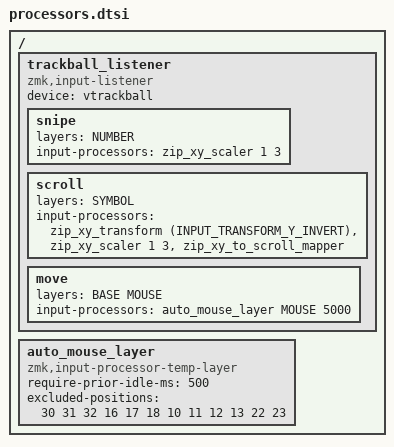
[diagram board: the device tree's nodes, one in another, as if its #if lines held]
/ {
  // Charybdis-specific processors
  #ifdef CHARYBDIS
  trackball_listener {
    compatible = "zmk,input-listener";
    device = <&vtrackball>;

    snipe {
      layers = <NUMBER>;
      input-processors = <&zip_xy_scaler 1 3>;
    };

    scroll {
      layers = <SYMBOL>;
      input-processors = <&zip_xy_transform (INPUT_TRANSFORM_Y_INVERT)>, 
        <&zip_xy_scaler 1 3>, 
        <&zip_xy_to_scroll_mapper>;
    };

    move {
      layers = <BASE MOUSE>;
      input-processors = <&auto_mouse_layer MOUSE 5000>;
    };
  };

  auto_mouse_layer: auto_mouse_layer {
    compatible = "zmk,input-processor-temp-layer";
    #input-processor-cells = <2>;
    require-prior-idle-ms = <500>;
    excluded-positions = <30 31 32 16 17 18 10 11 12 13 22 23>;
  };
  #endif

  // Corne-specific processors
  #ifdef CORNE
  #endif
};
